# iostm32f105xx register map
Registers are 32-bit, access not given, no defined reset value unless marked. A register's access mark holds for its fields unless they carry their own. Addresses are absolute; registers are grouped by the start of their names; [hi:lo] are bit positions; {n}, {i} and the like mark numbered series.

## CAN2
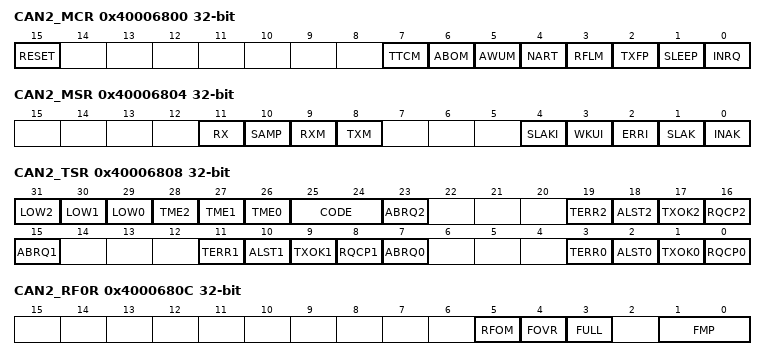
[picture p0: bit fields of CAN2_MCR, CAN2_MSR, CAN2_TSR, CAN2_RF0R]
0x40006800 CAN2_MCR
  [15] RESET, [7] TTCM, [6] ABOM, [5] AWUM, [4] NART, [3] RFLM, [2] TXFP, [1] SLEEP, [0] INRQ
0x40006804 CAN2_MSR
  [11] RX, [10] SAMP, [9] RXM, [8] TXM, [4] SLAKI, [3] WKUI, [2] ERRI, [1] SLAK, [0] INAK
0x40006808 CAN2_TSR
  [31] LOW2, [30] LOW1, [29] LOW0, [28] TME2, [27] TME1, [26] TME0, [25:24] CODE, [23] ABRQ2, [19] TERR2, [18] ALST2, [17] TXOK2, [16] RQCP2, [15] ABRQ1, [11] TERR1, [10] ALST1, [9] TXOK1, [8] RQCP1, [7] ABRQ0, [3] TERR0, [2] ALST0, [1] TXOK0, [0] RQCP0
0x4000680C CAN2_RF0R
  [5] RFOM, [4] FOVR, [3] FULL, [1:0] FMP
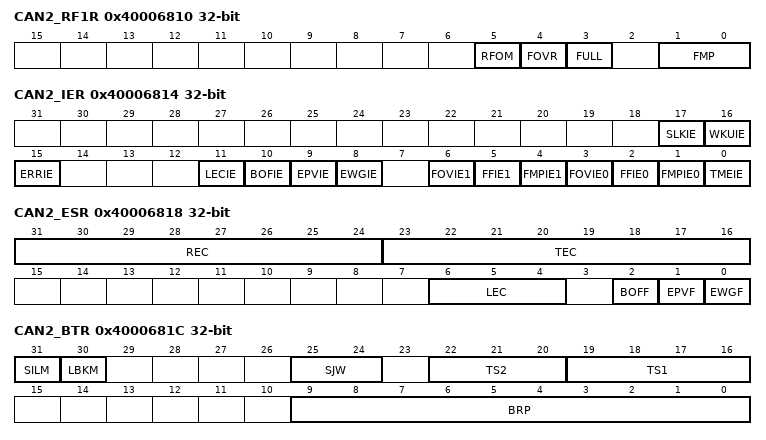
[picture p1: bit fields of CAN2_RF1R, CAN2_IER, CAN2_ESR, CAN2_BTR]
0x40006810 CAN2_RF1R
  [5] RFOM, [4] FOVR, [3] FULL, [1:0] FMP
0x40006814 CAN2_IER
  [17] SLKIE, [16] WKUIE, [15] ERRIE, [11] LECIE, [10] BOFIE, [9] EPVIE, [8] EWGIE, [6] FOVIE1, [5] FFIE1, [4] FMPIE1, [3] FOVIE0, [2] FFIE0, [1] FMPIE0, [0] TMEIE
0x40006818 CAN2_ESR
  [31:24] REC, [23:16] TEC, [6:4] LEC, [2] BOFF, [1] EPVF, [0] EWGF
0x4000681C CAN2_BTR
  [31] SILM, [30] LBKM, [25:24] SJW, [22:20] TS2, [19:16] TS1, [9:0] BRP
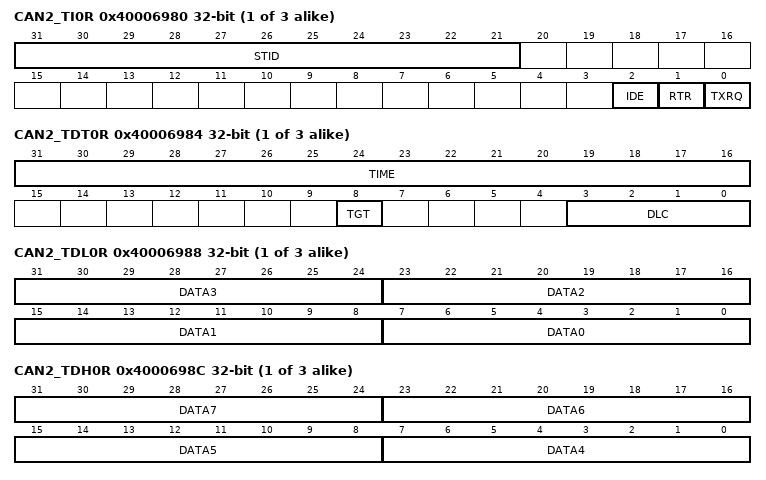
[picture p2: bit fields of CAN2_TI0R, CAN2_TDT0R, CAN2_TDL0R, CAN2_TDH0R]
{0x40006980+0x10*i} CAN2_TI{i}R (i=0..2)
  [31:21] STID, [2] IDE, [1] RTR, [0] TXRQ
{0x40006984+0x10*i} CAN2_TDT{i}R (i=0..2)
  [31:16] TIME, [8] TGT, [3:0] DLC
{0x40006988+0x10*i} CAN2_TDL{i}R (i=0..2)
  [8n+7:8n] DATA{n} (n=0..3)
{0x4000698C+0x10*i} CAN2_TDH{i}R (i=0..2)
  [8n-25:8n-32] DATA{n} (n=4..7)
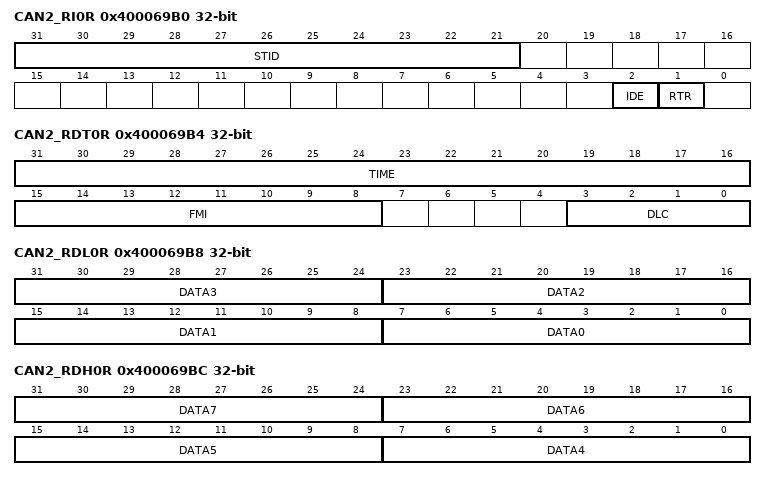
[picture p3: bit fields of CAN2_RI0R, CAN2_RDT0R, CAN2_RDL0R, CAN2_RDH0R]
0x400069B0 CAN2_RI0R
  [31:21] STID, [2] IDE, [1] RTR
0x400069B4 CAN2_RDT0R
  [31:16] TIME, [15:8] FMI, [3:0] DLC
0x400069B8 CAN2_RDL0R
  [8n+7:8n] DATA{n} (n=0..3)
0x400069BC CAN2_RDH0R
  [8n-25:8n-32] DATA{n} (n=4..7)
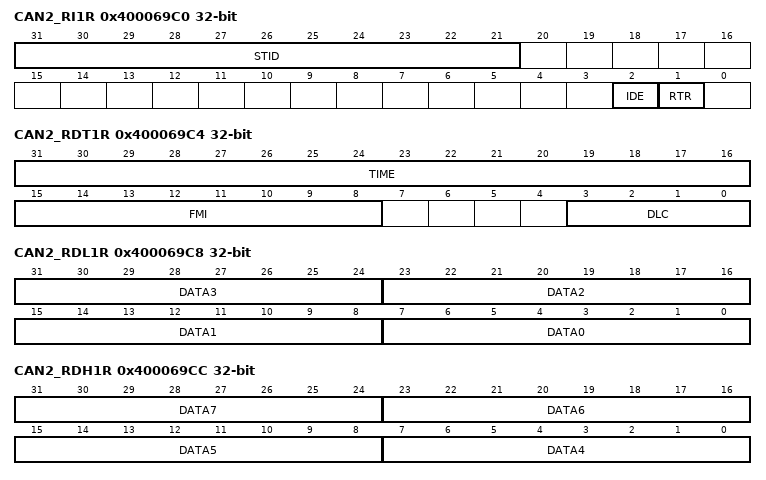
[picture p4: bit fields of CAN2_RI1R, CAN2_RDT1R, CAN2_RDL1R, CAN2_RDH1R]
0x400069C0 CAN2_RI1R
  [31:21] STID, [2] IDE, [1] RTR
0x400069C4 CAN2_RDT1R
  [31:16] TIME, [15:8] FMI, [3:0] DLC
0x400069C8 CAN2_RDL1R
  [8n+7:8n] DATA{n} (n=0..3)
0x400069CC CAN2_RDH1R
  [8n-25:8n-32] DATA{n} (n=4..7)

## CAN
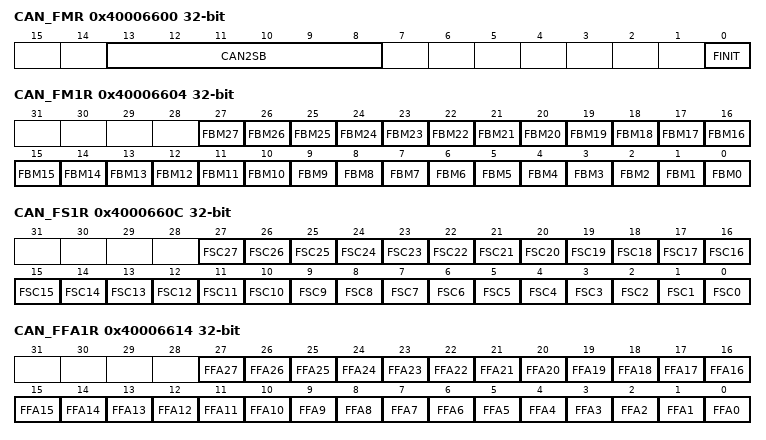
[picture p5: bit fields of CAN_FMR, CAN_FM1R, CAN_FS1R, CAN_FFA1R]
0x40006600 CAN_FMR
  [13:8] CAN2SB, [0] FINIT
0x40006604 CAN_FM1R
  [n] FBM{n} (n=0..27)
0x4000660C CAN_FS1R
  [n] FSC{n} (n=0..27)
0x40006614 CAN_FFA1R
  [n] FFA{n} (n=0..27)
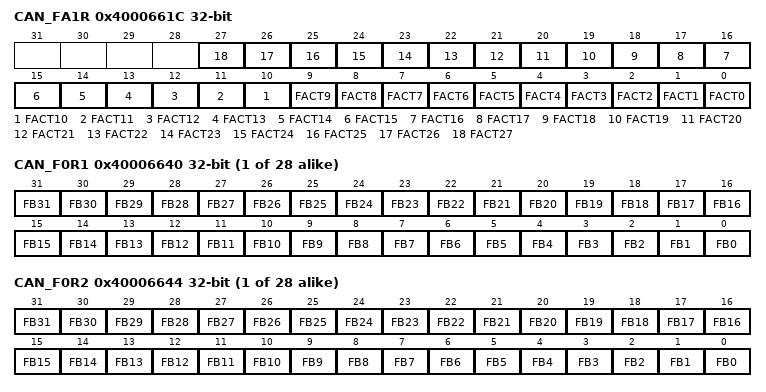
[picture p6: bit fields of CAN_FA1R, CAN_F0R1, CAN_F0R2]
0x4000661C CAN_FA1R
  [n] FACT{n} (n=0..27)
{0x40006640+8i} CAN_F{i}R1 (i=0..27)
  [n] FB{n} (n=0..31)
{0x40006644+8i} CAN_F{i}R2 (i=0..27)
  [n] FB{n} (n=0..31)

## I2C1
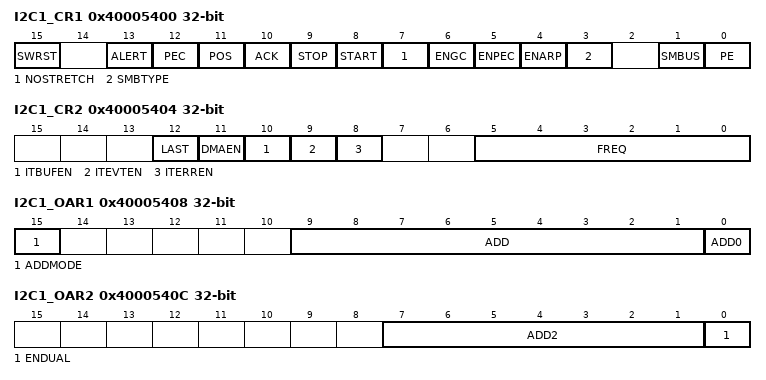
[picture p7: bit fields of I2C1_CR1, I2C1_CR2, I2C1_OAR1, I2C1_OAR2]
0x40005400 I2C1_CR1
  [15] SWRST, [13] ALERT, [12] PEC, [11] POS, [10] ACK, [9] STOP, [8] START, [7] NOSTRETCH, [6] ENGC, [5] ENPEC, [4] ENARP, [3] SMBTYPE, [1] SMBUS, [0] PE
0x40005404 I2C1_CR2
  [12] LAST, [11] DMAEN, [10] ITBUFEN, [9] ITEVTEN, [8] ITERREN, [5:0] FREQ
0x40005408 I2C1_OAR1
  [15] ADDMODE, [9:1] ADD, [0] ADD0
0x4000540C I2C1_OAR2
  [7:1] ADD2, [0] ENDUAL
0x40005410 I2C1_DR
  [7:0] DR
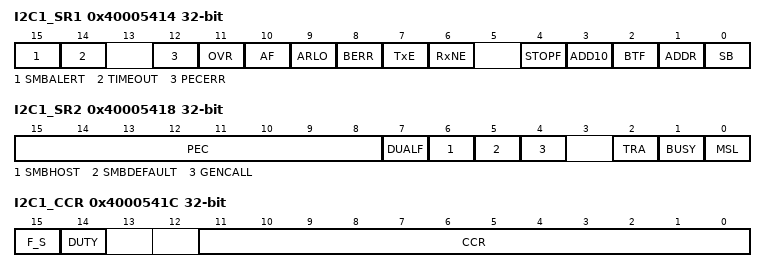
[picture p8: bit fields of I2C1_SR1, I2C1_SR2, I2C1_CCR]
0x40005414 I2C1_SR1
  [15] SMBALERT, [14] TIMEOUT, [12] PECERR, [11] OVR, [10] AF, [9] ARLO, [8] BERR, [7] TxE, [6] RxNE, [4] STOPF, [3] ADD10, [2] BTF, [1] ADDR, [0] SB
0x40005418 I2C1_SR2
  [15:8] PEC, [7] DUALF, [6] SMBHOST, [5] SMBDEFAULT, [4] GENCALL, [2] TRA, [1] BUSY, [0] MSL
0x4000541C I2C1_CCR
  [15] F_S, [14] DUTY, [11:0] CCR
0x40005420 I2C1_TRISE
  [5:0] TRISE

## I2C2
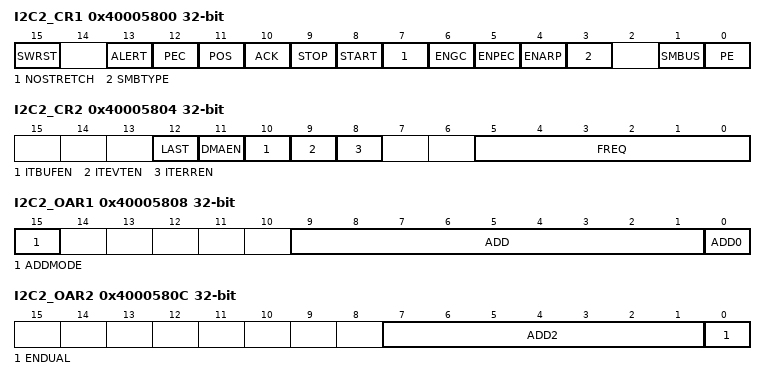
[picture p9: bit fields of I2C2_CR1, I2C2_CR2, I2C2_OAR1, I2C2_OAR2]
0x40005800 I2C2_CR1
  [15] SWRST, [13] ALERT, [12] PEC, [11] POS, [10] ACK, [9] STOP, [8] START, [7] NOSTRETCH, [6] ENGC, [5] ENPEC, [4] ENARP, [3] SMBTYPE, [1] SMBUS, [0] PE
0x40005804 I2C2_CR2
  [12] LAST, [11] DMAEN, [10] ITBUFEN, [9] ITEVTEN, [8] ITERREN, [5:0] FREQ
0x40005808 I2C2_OAR1
  [15] ADDMODE, [9:1] ADD, [0] ADD0
0x4000580C I2C2_OAR2
  [7:1] ADD2, [0] ENDUAL
0x40005810 I2C2_DR
  [7:0] DR
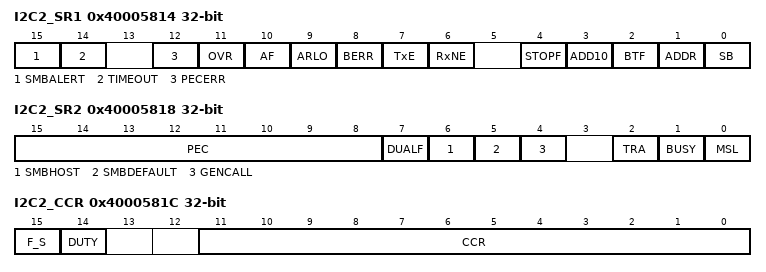
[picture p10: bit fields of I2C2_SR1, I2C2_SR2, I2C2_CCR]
0x40005814 I2C2_SR1
  [15] SMBALERT, [14] TIMEOUT, [12] PECERR, [11] OVR, [10] AF, [9] ARLO, [8] BERR, [7] TxE, [6] RxNE, [4] STOPF, [3] ADD10, [2] BTF, [1] ADDR, [0] SB
0x40005818 I2C2_SR2
  [15:8] PEC, [7] DUALF, [6] SMBHOST, [5] SMBDEFAULT, [4] GENCALL, [2] TRA, [1] BUSY, [0] MSL
0x4000581C I2C2_CCR
  [15] F_S, [14] DUTY, [11:0] CCR
0x40005820 I2C2_TRISE
  [5:0] TRISE
